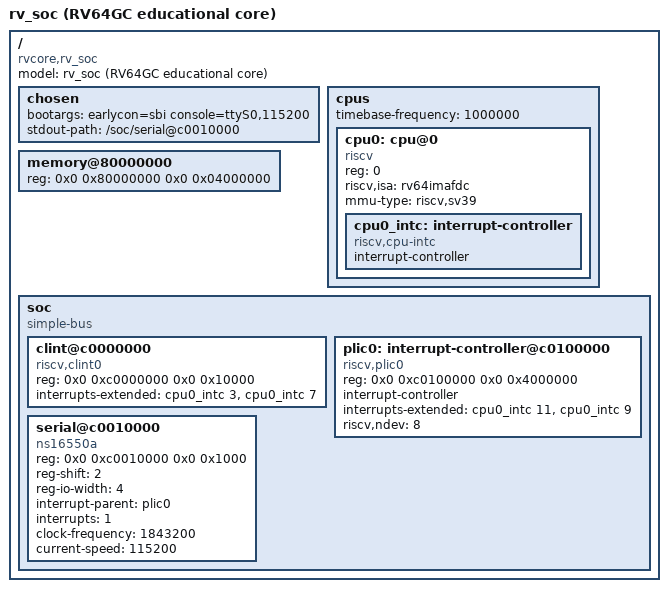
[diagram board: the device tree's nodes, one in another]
/dts-v1/;

/* Device tree for booting Linux on rv_soc in the sim boot harness.
 *
 * Differences from docs/opensbi/rv_soc.dts (the OpenSBI/mini-SBI DTB):
 *  - /memory is sized to the shared-DDR BFM (64 MiB), NOT 256 MiB.  OpenSBI
 *    relocates the FDT near the top of declared RAM; if /memory exceeds the BFM
 *    the relocation target reads X and the boot runs away (see docs/opensbi_sim.md
 *    "Final blocker").  Keep /memory <= the BFM DEPTH in tb_rv_boot_soc.sv.
 *  - riscv,isa = rv64imafdc only (no sstc/smaia/etc.) so Linux never touches an
 *    unimplemented CSR (e.g. stimecmp); it uses the SBI timer instead.
 *  - bootargs use earlycon=sbi for the earliest possible banner over the always-
 *    working OpenSBI console, then ttyS0 (our NS16550 UART) as the real console.
 */

/ {
    #address-cells = <2>;
    #size-cells = <2>;
    compatible = "rvcore,rv_soc";
    model = "rv_soc (RV64GC educational core)";

    chosen {
        bootargs = "earlycon=sbi console=ttyS0,115200";
        stdout-path = "/soc/serial@c0010000";
    };

    cpus {
        #address-cells = <1>;
        #size-cells = <0>;
        timebase-frequency = <1000000>;   /* CLINT mtime ticks once per cycle */

        cpu0: cpu@0 {
            device_type = "cpu";
            reg = <0>;
            compatible = "riscv";
            riscv,isa = "rv64imafdc";
            mmu-type = "riscv,sv39";
            status = "okay";

            cpu0_intc: interrupt-controller {
                #interrupt-cells = <1>;
                interrupt-controller;
                compatible = "riscv,cpu-intc";
            };
        };
    };

    /* 64 MiB == the rv_axi_dualport_mem_bfm DEPTH (1<<26) in tb_rv_boot_soc.sv. */
    memory@80000000 {
        device_type = "memory";
        reg = <0x0 0x80000000  0x0 0x04000000>;
    };

    soc {
        #address-cells = <2>;
        #size-cells = <2>;
        compatible = "simple-bus";
        ranges;

        clint@c0000000 {
            compatible = "riscv,clint0";
            reg = <0x0 0xc0000000  0x0 0x10000>;
            interrupts-extended = <&cpu0_intc 3 &cpu0_intc 7>;  /* MSIP, MTIP */
        };

        plic0: interrupt-controller@c0100000 {
            compatible = "riscv,plic0";
            reg = <0x0 0xc0100000  0x0 0x4000000>;
            #interrupt-cells = <1>;
            interrupt-controller;
            interrupts-extended = <&cpu0_intc 11 &cpu0_intc 9>; /* MEIP, SEIP */
            riscv,ndev = <8>;
        };

        serial@c0010000 {
            compatible = "ns16550a";
            reg = <0x0 0xc0010000  0x0 0x1000>;
            reg-shift = <2>;
            reg-io-width = <4>;
            interrupt-parent = <&plic0>;
            interrupts = <1>;
            clock-frequency = <1843200>;
            current-speed = <115200>;
        };
    };
};
